AUTOSAR XML (schema 00049)
package /Application/DltConfig
  dlt log channel to process mapping DltLogChannelToProcessMapping_SC_PDW_TO_SC_PDW: dlt-log-channel=SC_PDW, process=SC_PDW
package /Application/Executable
  executable SC_PDW: category=APPLICATION_LEVEL, logging-behavior=USES-LOGGING, reporting-behavior=REPORTS-EXECUTION-STATE, version=1.0.0
    root sw component prototype RootSwComponent: application-type=SC_PDW
package /Application/Manifest
  5 x service instance to port prototype mapping, all with process=SC_PDW:
    SC_PDW_RootSwComponent_PdwFront: port-prototype=RootSwComponent.PdwFront, service-instance=EEVP_PDW_Provider_PdwFrontService
    SC_PDW_RootSwComponent_PdwRear: port-prototype=RootSwComponent.PdwRear, service-instance=EEVP_PDW_Provider_PdwRearService
    SC_PDW_RootSwComponent_UssFront: port-prototype=RootSwComponent.UssFront, service-instance=EEVP_PDW_Consumer_UssFrontInput
    SC_PDW_RootSwComponent_UssRear: port-prototype=RootSwComponent.UssRear, service-instance=EEVP_PDW_Consumer_UssRearInput
    SC_PDW_RootSwComponent_VehicleInfo: port-prototype=RootSwComponent.VehicleInfo, service-instance=EEVP_PDW_Consumer_VehicleInfo
package /Application/Process
  process SC_PDW: executable=SC_PDW, state-dependent-startup-config{function-group-state=SC.On, resource-group=DefaultResourceGroup, startup-config=DefaultStartupConfig}
    process state machine SC_PDW: type=ProcessState
package /Application/SwComponent
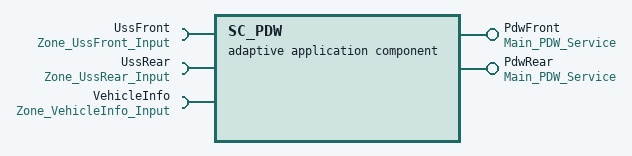
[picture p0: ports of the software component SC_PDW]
  adaptive application sw component type SC_PDW
    provide port PdwFront: provided-interface=Main_PDW_Service
    provide port PdwRear: provided-interface=Main_PDW_Service
    require port UssFront: required-interface=Zone_UssFront_Input
    require port UssRear: required-interface=Zone_UssRear_Input
    require port VehicleInfo: required-interface=Zone_VehicleInfo_Input
